# PIC32MZ0512EFF144 device description
Architecture: 32xxxx; Family: PIC32MZEF; Series: PIC32MZ
Registers are 32-bit, read-write, no defined reset value unless marked. A register's access mark holds for its fields unless they carry their own. Offsets are from the block's base; [hi:lo] are bit positions; {n}, {i} and the like mark numbered series; 'fields as' and 'values as' point back to an identical list.

## CFG
Instances: CFG 0x1f800000 in periph_pb1_std
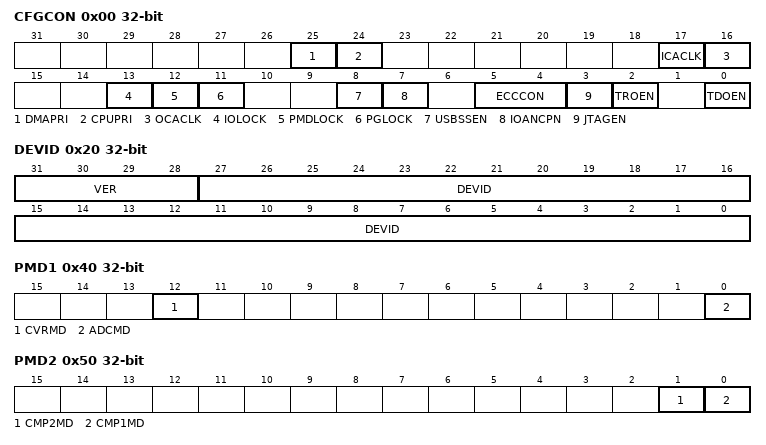
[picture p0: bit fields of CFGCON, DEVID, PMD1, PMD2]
0x00 CFGCON — Configuration Control Register
  [25] DMAPRI — DMA Read and DMA Write Arbitration Priority to SRAM bit(1)
    1=DMA gets High Priority access to SRAM; 0=DMA uses Least Recently Serviced Arbitration (same as other initiators)
  [24] CPUPRI — CPU Arbitration Priority to SRAM When Servicing an Interrupt bit(1)
    1=CPU gets High Priority access to SRAM; 0=CPU uses Least Recently Serviced Arbitration (same as other initiators)
  [17] ICACLK — Input Capture Alternate Clock Selection bit(1)
    1=Input Capture modules use an alternative Timer pair as their timebase clock; 0=All Input Capture modules use Timer2/3 as their timebase clock
  [16] OCACLK — Output Compare Alternate Clock Selection bit(1)
    1=Output Compare modules use an alternative Timer pair as their timebase clock; 0=All Output Compare modules use Timer2/3 as their timebase clock
  [13] IOLOCK — Peripheral Pin Select Lock bit(1)
    1=Peripheral Pin Select is locked. Writes to PPS registers are not allowed; 0=Peripheral Pin Select is not locked. Writes to PPS registers are allowed
  [12] PMDLOCK — Peripheral Module Disable bit(1)
    1=Peripheral module is locked. Writes to PMD registers are not allowed; 0=Peripheral module is not locked. Writes to PMD registers are allowed
  [11] PGLOCK — Permission Group Lock bit(1)
    1=Permission Group registers are locked. Writes to PG registers are not allowed; 0=Permission Group registers are not locked. Writes to PG registers are allowed
  [8] USBSSEN — USB Suspend Sleep Enable bit(1)
    1=USB PHY clock is shut down when Sleep mode is active; 0=USB PHY clock continues to run when Sleep is active
  [7] IOANCPN
  [5:4] ECCCON — Flash ECC Configuration bits
    3=ECC and dynamic ECC are disabled (ECCCON bits are writable); 2=ECC and dynamic ECC are disabled (ECCCON bits are locked); 1=Dynamic Flash ECC is enabled (ECCCON bits are locked); 0=Flash ECC is enabled (ECCCON bits are locked; disables word Flash writes)
  [3] JTAGEN — JTAG Port Enable bit
    1=Enable the JTAG port; 0=Disable the JTAG port
  [2] TROEN — Trace Output Enable bit
    1=Enable trace outputs and start trace clock (trace probe must be present); 0=Disable trace outputs and stop trace clock
  [0] TDOEN — TDO Enable for 2-Wire JTAG
    1=2-wire JTAG protocol uses TDO; 0=2-wire JTAG protocol does not use TDO
0x20 DEVID — Device and Revision ID Register
  [31:28] VER, [27:0] DEVID
0x30 SYSKEY
0x40 PMD1
  [12] CVRMD, [0] ADCMD
0x50 PMD2
  [1] CMP2MD, [0] CMP1MD
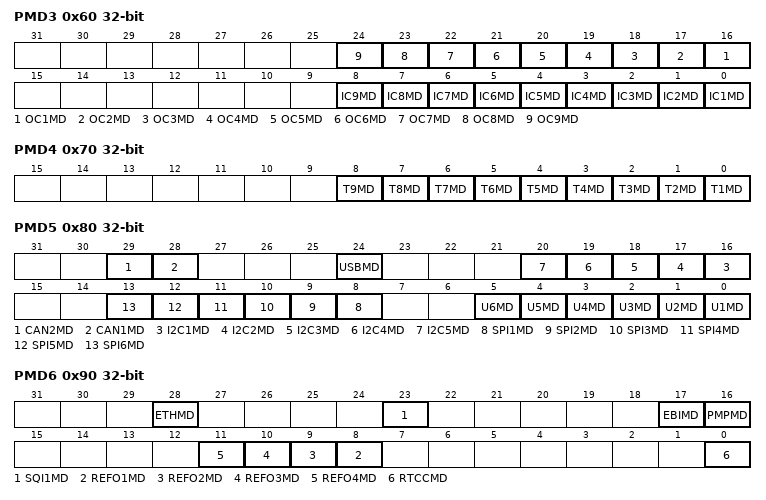
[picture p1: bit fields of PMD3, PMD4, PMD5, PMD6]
0x60 PMD3
  [n+15] OC{n}MD (n=1..9), [n-1] IC{n}MD (n=1..9)
0x70 PMD4
  [n-1] T{n}MD (n=1..9)
0x80 PMD5
  [29] CAN2MD, [28] CAN1MD, [24] USBMD, [n+15] I2C{n}MD (n=1..5), [n+7] SPI{n}MD (n=1..6), [n-1] U{n}MD (n=1..6)
0x90 PMD6
  [28] ETHMD, [23] SQI1MD, [17] EBIMD, [16] PMPMD, [n+7] REFO{n}MD (n=1..4), [0] RTCCMD
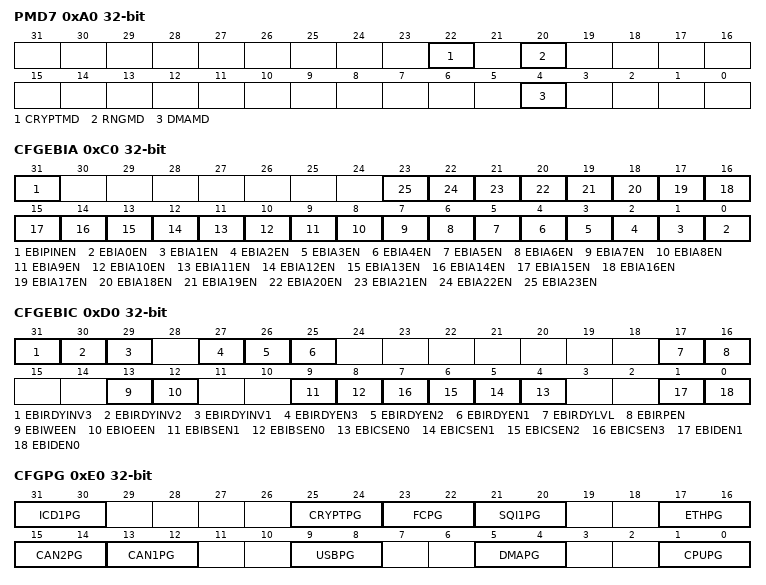
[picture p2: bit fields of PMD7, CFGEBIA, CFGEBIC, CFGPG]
0xA0 PMD7
  [22] CRYPTMD, [20] RNGMD, [4] DMAMD
0xC0 CFGEBIA — External Bus Interface Address Pin Configuration Register
  [31] EBIPINEN — EBI Pin Enable bit
    1=EBI controls access of pins shared with PMP; 0=Pins shared with EBI are available for general use
  [n] EBIA{n}EN (n=0..23) — EBI Address Pin Enable bits
    1=EBIAx pin is enabled for use by EBI; 0=EBIAx pin has is available for general use
0xD0 CFGEBIC — External Bus Interface Control Pin Configuration Register
  [31] EBIRDYINV3 — EBIRDY3 Inversion Control bit
    1=Invert EBIRDY3 pin before use; 0=Do not invert EBIRDY3 pin before use
  [30] EBIRDYINV2 — EBIRDY2 Inversion Control bit
    1=Invert EBIRDY2 pin before use; 0=Do not invert EBIRDY2 pin before use
  [29] EBIRDYINV1 — EBIRDY1 Inversion Control bit
    1=Invert EBIRDY1 pin before use; 0=Do not invert EBIRDY1 pin before use
  [27] EBIRDYEN3 — EBIRDY3 Pin Enable bit
    1=EBIRDY3 pin is enabled for use by the EBI module; 0=EBIRDY3 pin is available for general use
  [26] EBIRDYEN2 — EBIRDY2 Pin Enable bit
    1=EBIRDY2 pin is enabled for use by the EBI module; 0=EBIRDY2 pin is available for general use
  [25] EBIRDYEN1 — EBIRDY1 Pin Enable bit
    1=EBIRDY1 pin is enabled for use by the EBI module; 0=EBIRDY1 pin is available for general use
  [17] EBIRDYLVL — EBIRDYx Pin Sensitivity Control bit
    1=Use level detect for EBIRDYx pins; 0=Use edge detect for EBIRDYx pins
  [16] EBIRPEN — /EBIRP Pin Sensitivity Control bit
    1=/EBIRP pin is enabled for use by the EBI module; 0=/EBIRP pin is available for general use
  [13] EBIWEEN — /EBIWE Pin Enable bit
    1=/EBIWE pin is enabled for use by the EBI module; 0=/EBIWE pin is available for general use
  [12] EBIOEEN — /EBIOE Pin Enable bit
    1=/EBIOE pin is enabled for use by the EBI module; 0=/EBIOE pin is available for general use
  [9] EBIBSEN1 — /EBIBS1 Pin Enable bit
    1=/EBIBS1 pin is enabled for use by the EBI module; 0=/EBIBS1 pin is available for general use
  [8] EBIBSEN0 — /EBIBS0 Pin Enable bit
    1=/EBIBS0 pin is enabled for use by the EBI module; 0=/EBIBS0 pin is available for general use
  [n+4] EBICSEN{n} (n=0..3) — /EBICS{n} Pin Enable bit
    1=/EBICS{n} pin is enabled for use by the EBI module; 0=/EBICS{n} pin is available for general use
  [1] EBIDEN1 — EBI Data Upper Byte Pin Enable bit
    1=EBID pins are enabled for use by the EBI module; 0=EBID pins have reverted to general use
  [0] EBIDEN0 — EBI Data Lower Byte Pin Enable bit
    values as EBIDEN1
0xE0 CFGPG — Permission Group Configuration Register
  [31:30] ICD1PG
  [25:24] CRYPTPG — Crypto Engine Permission Group bits
    {v}=Initiator is assigned to Permission Group {v} (v=0..3)
  [23:22] FCPG
  [21:20] SQI1PG
  [17:16] ETHPG
  [15:14] CAN2PG
  [13:12] CAN1PG
  [9:8] USBPG
  [5:4] DMAPG
  [1:0] CPUPG
Value list DEVID__VER: 0x10000000=Revision A1; 0x30000000=Revision A3; 0x60000000=Revision B2
Value list CFGCON__IOANCPEN: 128=Charge pump is enabled; 0=Charge pump is disabled
